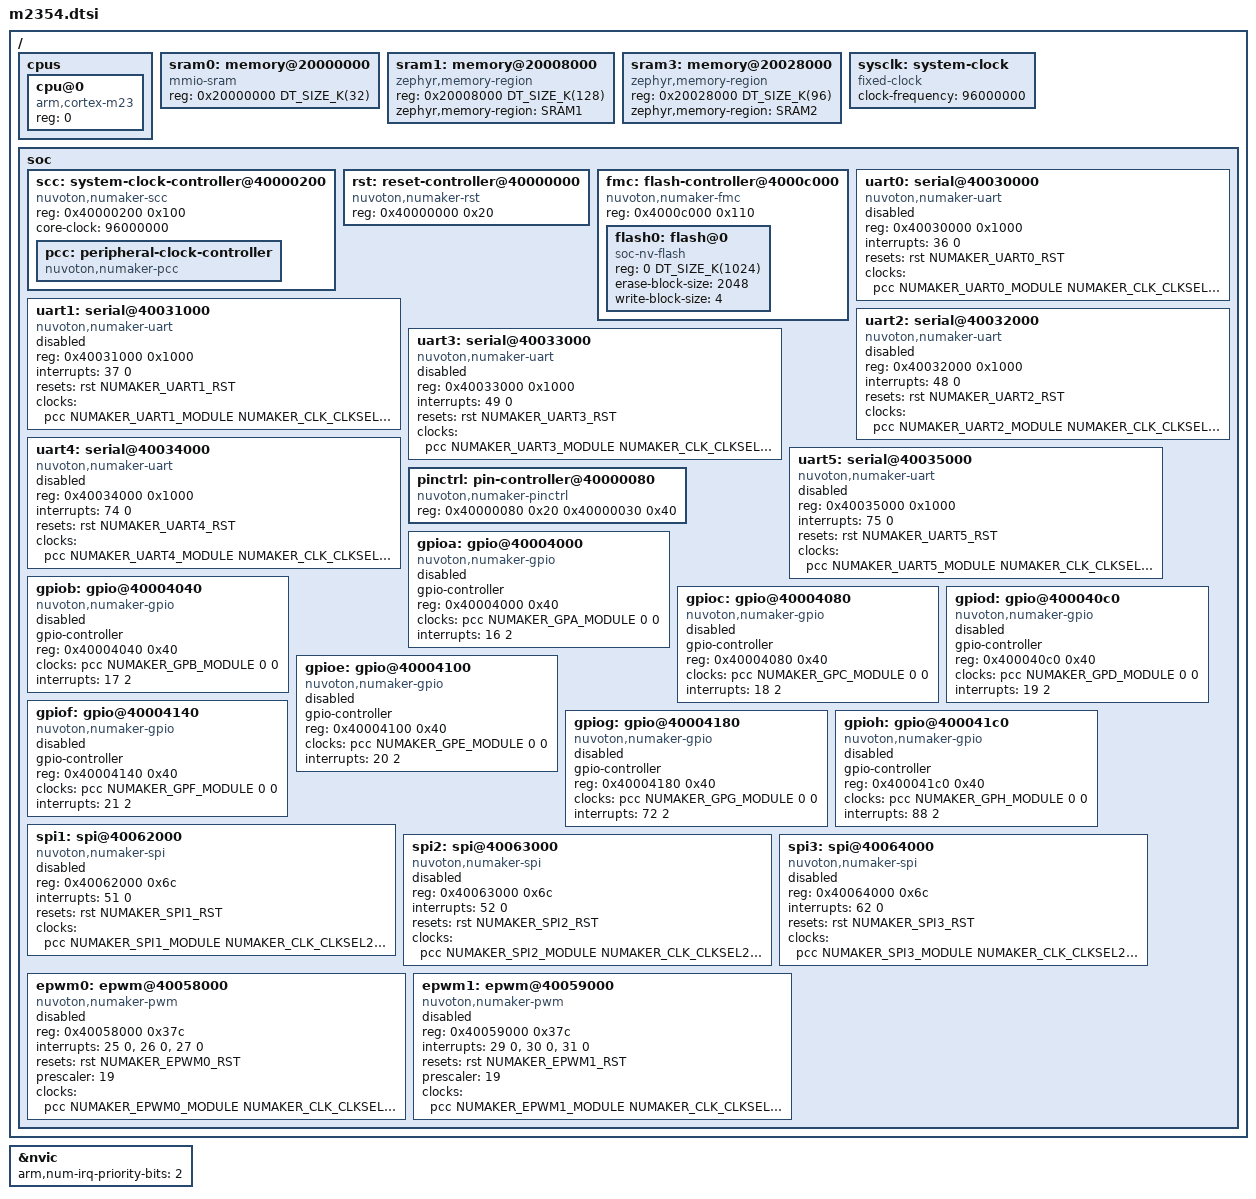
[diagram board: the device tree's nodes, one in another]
/*
 * Copyright (c) 2023 Nuvoton Technology Corporation.
 *
 * SPDX-License-Identifier: Apache-2.0
 */

 #include <arm/armv8-m.dtsi>
 #include <mem.h>
 #include <zephyr/dt-bindings/pinctrl/numaker-m2354-pinctrl.h>
 #include <zephyr/dt-bindings/clock/numaker_m2354_clock.h>
 #include <zephyr/dt-bindings/reset/numaker_m2354_reset.h>
 #include <zephyr/dt-bindings/gpio/gpio.h>

 / {
    //  chosen {
    //      zephyr,flash-controller = &fmc;
    //  };

     cpus {
         #address-cells = <1>;
         #size-cells = <0>;

         cpu@0 {
             device_type = "cpu";
             compatible = "arm,cortex-m23";
             reg = <0>;
         };
     };

//      sram0: memory@20000000 {
//          compatible = "mmio-sram";
//          reg = <0x20000000 DT_SIZE_K(256)>;
//      };
     sram0: memory@20000000 {
	compatible = "mmio-sram";
	reg = <0x20000000 DT_SIZE_K(32)>;
     };
     sram1: memory@20008000 {
	compatible = "zephyr,memory-region", "mmio-sram";
	reg = <0x20008000 DT_SIZE_K(128)>;
	zephyr,memory-region = "SRAM1";
     };
     sram3: memory@20028000 {
	compatible = "zephyr,memory-region", "mmio-sram";
	reg = <0x20028000 DT_SIZE_K(96)>;
	zephyr,memory-region = "SRAM2";
     };

     sysclk: system-clock {
         compatible = "fixed-clock";
         clock-frequency = <96000000>;
         #clock-cells = <0>;
     };

     soc {
         scc: system-clock-controller@40000200 {
             compatible = "nuvoton,numaker-scc";
             reg = <0x40000200 0x100>;
             #clock-cells = <0>;
             /* hxt = "enable"; */
             /* lxt = "enable"; */
        //      clk-pclkdiv = <(NUMAKER_CLK_PCLKDIV_APB0DIV_DIV2 |
        //               NUMAKER_CLK_PCLKDIV_APB1DIV_DIV2)>;
             core-clock = <96000000>;

             pcc: peripheral-clock-controller {
                 compatible = "nuvoton,numaker-pcc";
                 #clock-cells = <3>;
             };
         };

         rst: reset-controller@40000000 {
             compatible = "nuvoton,numaker-rst";
             reg = <0x40000000 0x20>;
             #reset-cells = <1>;
             status = "okay";
         };

         fmc: flash-controller@4000c000 {
             compatible = "nuvoton,numaker-fmc";
             reg = <0x4000c000 0x110>;
             #address-cells = <1>;
             #size-cells = <1>;

             flash0: flash@0 {
                 compatible = "soc-nv-flash";
                 reg = <0 DT_SIZE_K(1024)>;
                 erase-block-size = <2048>;
                 write-block-size = <4>;
             };
         };

         uart0: serial@40030000 {
             compatible = "nuvoton,numaker-uart";
             reg = <0x40030000 0x1000>;
             interrupts = <36 0>;
             resets = <&rst NUMAKER_UART0_RST>;
             clocks = <&pcc NUMAKER_UART0_MODULE NUMAKER_CLK_CLKSEL2_UART0SEL_HIRC
                   NUMAKER_CLK_CLKDIV0_UART0(1)>;
             status = "disabled";
         };

         uart1: serial@40031000 {
             compatible = "nuvoton,numaker-uart";
             reg = <0x40031000 0x1000>;
             interrupts = <37 0>;
             resets = <&rst NUMAKER_UART1_RST>;
             clocks = <&pcc NUMAKER_UART1_MODULE NUMAKER_CLK_CLKSEL2_UART1SEL_HIRC
                   NUMAKER_CLK_CLKDIV0_UART1(1)>;
             status = "disabled";
         };

         uart2: serial@40032000 {
             compatible = "nuvoton,numaker-uart";
             reg = <0x40032000 0x1000>;
             interrupts = <48 0>;
             resets = <&rst NUMAKER_UART2_RST>;
             clocks = <&pcc NUMAKER_UART2_MODULE NUMAKER_CLK_CLKSEL2_UART2SEL_HIRC
                   NUMAKER_CLK_CLKDIV4_UART2(1)>;
             status = "disabled";
         };

         uart3: serial@40033000 {
             compatible = "nuvoton,numaker-uart";
             reg = <0x40033000 0x1000>;
             interrupts = <49 0>;
             resets = <&rst NUMAKER_UART3_RST>;
             clocks = <&pcc NUMAKER_UART3_MODULE NUMAKER_CLK_CLKSEL2_UART3SEL_HIRC
                   NUMAKER_CLK_CLKDIV4_UART3(1)>;
             status = "disabled";
         };

         uart4: serial@40034000 {
             compatible = "nuvoton,numaker-uart";
             reg = <0x40034000 0x1000>;
             interrupts = <74 0>;
             resets = <&rst NUMAKER_UART4_RST>;
             clocks = <&pcc NUMAKER_UART4_MODULE NUMAKER_CLK_CLKSEL3_UART4SEL_HIRC
                   NUMAKER_CLK_CLKDIV4_UART4(1)>;
             status = "disabled";
         };

         uart5: serial@40035000 {
             compatible = "nuvoton,numaker-uart";
             reg = <0x40035000 0x1000>;
             interrupts = <75 0>;
             resets = <&rst NUMAKER_UART5_RST>;
             clocks = <&pcc NUMAKER_UART5_MODULE NUMAKER_CLK_CLKSEL3_UART5SEL_HIRC
                   NUMAKER_CLK_CLKDIV4_UART5(1)>;
             status = "disabled";
         };

         pinctrl: pin-controller@40000080 {
             compatible = "nuvoton,numaker-pinctrl";
             reg = <0x40000080 0x20
                    0x40000030 0x40>;
             reg-names = "mfos", "mfp";
             status = "okay";
         };

         gpioa: gpio@40004000 {
             compatible = "nuvoton,numaker-gpio";
             gpio-controller;
             #gpio-cells = <2>;
             reg = <0x40004000 0x40>;
             clocks = <&pcc NUMAKER_GPA_MODULE 0 0>;
             status = "disabled";
             interrupts = <16 2>;
         };

         gpiob: gpio@40004040 {
             compatible = "nuvoton,numaker-gpio";
             gpio-controller;
             #gpio-cells = <2>;
             reg = <0x40004040 0x40>;
             clocks = <&pcc NUMAKER_GPB_MODULE 0 0>;
             status = "disabled";
             interrupts = <17 2>;
         };

         gpioc: gpio@40004080 {
             compatible = "nuvoton,numaker-gpio";
             gpio-controller;
             #gpio-cells = <2>;
             reg = <0x40004080 0x40>;
             clocks = <&pcc NUMAKER_GPC_MODULE 0 0>;
             status = "disabled";
             interrupts = <18 2>;
         };

         gpiod: gpio@400040c0 {
             compatible = "nuvoton,numaker-gpio";
             gpio-controller;
             #gpio-cells = <2>;
             reg = <0x400040c0 0x40>;
             clocks = <&pcc NUMAKER_GPD_MODULE 0 0>;
             status = "disabled";
             interrupts = <19 2>;
         };

         gpioe: gpio@40004100 {
             compatible = "nuvoton,numaker-gpio";
             gpio-controller;
             #gpio-cells = <2>;
             reg = <0x40004100 0x40>;
             clocks = <&pcc NUMAKER_GPE_MODULE 0 0>;
             status = "disabled";
             interrupts = <20 2>;
         };

         gpiof: gpio@40004140 {
             compatible = "nuvoton,numaker-gpio";
             gpio-controller;
             #gpio-cells = <2>;
             reg = <0x40004140 0x40>;
             clocks = <&pcc NUMAKER_GPF_MODULE 0 0>;
             status = "disabled";
             interrupts = <21 2>;
         };

         gpiog: gpio@40004180 {
             compatible = "nuvoton,numaker-gpio";
             gpio-controller;
             #gpio-cells = <2>;
             reg = <0x40004180 0x40>;
             clocks = <&pcc NUMAKER_GPG_MODULE 0 0>;
             status = "disabled";
             interrupts = <72 2>;
         };

         gpioh: gpio@400041c0 {
             compatible = "nuvoton,numaker-gpio";
             gpio-controller;
             #gpio-cells = <2>;
             reg = <0x400041c0 0x40>;
             clocks = <&pcc NUMAKER_GPH_MODULE 0 0>;
             status = "disabled";
             interrupts = <88 2>;
         };

        //  spi0: spi@40061000 {
        //      compatible = "nuvoton,numaker-spi";
        //      reg = <0x40061000 0x6c>;
        //      interrupts = <23 0>;
        //      resets = <&rst NUMAKER_SPI0_RST>;
        //      clocks = <&pcc NUMAKER_SPI0_MODULE NUMAKER_CLK_CLKSEL2_SPI0SEL_HIRC 0>;
        //      #address-cells = <1>;
        //      #size-cells = <0>;
        //      status = "disabled";
        //  };

         spi1: spi@40062000 {
             compatible = "nuvoton,numaker-spi";
             reg = <0x40062000 0x6c>;
             interrupts = <51 0>;
             resets = <&rst NUMAKER_SPI1_RST>;
             clocks = <&pcc NUMAKER_SPI1_MODULE NUMAKER_CLK_CLKSEL2_SPI1SEL_HIRC 0>;
             #address-cells = <1>;
             #size-cells = <0>;
             status = "disabled";
         };

         spi2: spi@40063000 {
             compatible = "nuvoton,numaker-spi";
             reg = <0x40063000 0x6c>;
             interrupts = <52 0>;
             resets = <&rst NUMAKER_SPI2_RST>;
             clocks = <&pcc NUMAKER_SPI2_MODULE NUMAKER_CLK_CLKSEL2_SPI2SEL_HIRC 0>;
             #address-cells = <1>;
             #size-cells = <0>;
             status = "disabled";
         };

         spi3: spi@40064000 {
             compatible = "nuvoton,numaker-spi";
             reg = <0x40064000 0x6c>;
             interrupts = <62 0>;
             resets = <&rst NUMAKER_SPI3_RST>;
             clocks = <&pcc NUMAKER_SPI3_MODULE NUMAKER_CLK_CLKSEL2_SPI3SEL_HIRC 0>;
             #address-cells = <1>;
             #size-cells = <0>;
             status = "disabled";
         };

         epwm0: epwm@40058000 {
             compatible = "nuvoton,numaker-pwm";
             reg = <0x40058000 0x37c>;
             interrupts = <25 0>, <26 0>, <27 0>;
             interrupt-names = "pair0", "pair1", "pair2";
             resets = <&rst NUMAKER_EPWM0_RST>;
             prescaler = <19>;
             clocks = <&pcc NUMAKER_EPWM0_MODULE NUMAKER_CLK_CLKSEL2_EPWM0SEL_PCLK0 0>;
             #pwm-cells = <3>;
             status = "disabled";
         };

         epwm1: epwm@40059000 {
             compatible = "nuvoton,numaker-pwm";
             reg = <0x40059000 0x37c>;
             interrupts = <29 0>, <30 0>, <31 0>;
             interrupt-names = "pair0", "pair1", "pair2";
             resets = <&rst NUMAKER_EPWM1_RST>;
             prescaler = <19>;
             clocks = <&pcc NUMAKER_EPWM1_MODULE NUMAKER_CLK_CLKSEL2_EPWM1SEL_PCLK1 0>;
             #pwm-cells = <3>;
             status = "disabled";
         };
     };
 };

 &nvic {
     arm,num-irq-priority-bits = <2>;
 };
